# RTS5918 register map
Vendor: Realtek Semiconductor Corp.; Series: RTS5918 Series; File version: 1.00
CPU: ARMV8MML r0p0, little endian, MPU, FPU, VTOR, 3 interrupt priority bits, 8 SAU regions
Registers are 32-bit, read-write, reset 0x0 unless marked. A register's access mark holds for its fields unless they carry their own. Offsets are from the block's base; [hi:lo] are bit positions; {n}, {i} and the like mark numbered series; 'fields as' and 'values as' point back to an identical list.

## DMA — DMA Controller
Base 0x40002000
{0x0+0x58*i} SAR{i} (i=0..7) — SOURCE ADDRESS REGISTER
{0x8+0x58*i} DAR{i} (i=0..7) — DESTINATION ADDRESS REGISTER
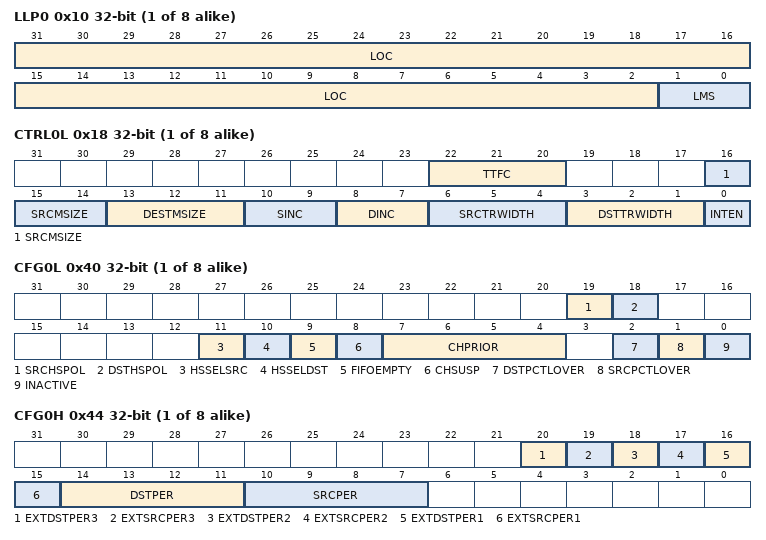
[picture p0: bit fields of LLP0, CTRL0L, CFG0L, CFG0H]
{0x10+0x58*i} LLP{i} (i=0..7) — LINKED LIST POINTER REGISTER
  [31:2] LOC — Starting Address In Memory
  [1:0] LMS — List Master Select
{0x18+0x58*i} CTRL{i}L (i=0..7) — CONTROL REGISTER LOW
  [22:20] TTFC — Transfer Type and Flow Control
    0=M2M (Memory to Memory); 1=M2P (Memory to Peripheral); 2=P2M (Peripheral to Memory); 3=P2P (Peripheral to Peripheral)
  [16:14] SRCMSIZE — Source Burst Transaction Length
    0=Transfer data item x1; 1=x4 (Transfer data item x4); 2=x8 (Transfer data item x8); 3=x16 (Transfer data item x16); 4=x32 (Transfer data item x32); 5=x64 (Transfer data item x64); 6=x128 (Transfer data item x128); 7=x256 (Transfer data item x256)
  [13:11] DESTMSIZE — Destination Burst Transaction Length
    values as SRCMSIZE
  [10:9] SINC — Source Address Increment
    0=INC (Increment); 2=FIXED (Fixed (No change)); other=NOT_USED (Do not use.)
  [8:7] DINC — Destination Address Increment
    values as SINC
  [6:4] SRCTRWIDTH — Source Transfer Width
    0=8_BIT; 1=16_BIT; 2=32_BIT; 3=64_BIT; 4=128_BIT; 5=256_BIT; other=NOT_USED (Do not use.)
  [3:1] DSTTRWIDTH — Destination Transfer Width
    values as SRCTRWIDTH
  [0] INTEN — Interrupt Enable Bit
    0=DISABLE (Disable interrup); 1=ENABLE (Enable interrup)
{0x1C+0x58*i} CTRL{i}H (i=0..7) — CONTROL REGISTER HIGH
  [31:0] BLOCKTS — Block Transfer Size
{0x40+0x58*i} CFG{i}L (i=0..7) — CONFIGURATION REGISTER LOW
  [19] SRCHSPOL — Source Handshaking Interface Polarity
  [18] DSTHSPOL — Destination Handshaking Interface Polarity
  [11] HSSELSRC — Source Software or Hardware Handshaking Select
  [10] HSSELDST — Destination Software or Hardware Handshaking Select
  [9] FIFOEMPTY ro — Indicates if there is data left in the channel FIFO
  [8] CHSUSP — Channel Suspend
  [7:4] CHPRIOR — Channel Priority
  [2] DSTPCTLOVER ro — DMA destination bus protocol finish, indicating the current read command has finished
  [1] SRCPCTLOVER ro — DMA Source bus protocol finish, indicating the current read command has finished
  [0] INACTIVE ro — Indicates if the channel is inactive
{0x44+0x58*i} CFG{i}H (i=0..7) — CONFIGURATION REGISTER HIGH
  [20] EXTDSTPER3 — The extened 6th bit of DSTPER
  [19] EXTSRCPER3 — The extened 6th bit of SRCPER
  [18] EXTDSTPER2 — The extened 5th bit of DSTPER
  [17] EXTSRCPER2 — The extened 5th bit of SRCPER
  [16] EXTDSTPER1 — The extened 4th bit of DSTPER
  [15] EXTSRCPER1 — The extened 4th bit of SRCPER
  [14:11] DSTPER — Assigns a Hardware Handshaking Interface to The Destination of Channel
  [10:7] SRCPER — Assigns a Hardware Handshaking Interface to The Source of Channel
0x2C0 RAWTFR — RAW STATUS FOR INTTFR INTERRUPT REGISTER
0x2C8 RAWBLOCK — RAW STATUS FOR INTBLOCK REGISTER
0x2D0 RAWSRCTRAN — RAW STATUS FOR INTSRCTRAN INTERRUPT REGISTER
0x2D8 RAWDSTTRAN — RAW STATUS FOR INTDSTTRAN INTERRUPT REGISTER
0x2E0 RAWERR — RAW STATUS FOR INTERR INTERRUPT REGISTER
0x2E8 STSTFR — INTERRUPT STATUS FOR INTTFR INTERRUPT REGISTER
0x2F0 STSBLOCK — INTERRUPT STATUS FOR INTBLOCK REGISTER
0x2F8 STSSRCTRAN — INTERRUPT STATUS FOR INTSRCTRAN INTERRUPT REGISTER
0x300 STSDSTTRAN — INTERRUPT STATUS FOR INTDSTTRAN INTERRUPT REGISTER
0x308 STSERR — INTERRUPT STATUS FOR INTERR INTERRUPT REGISTER
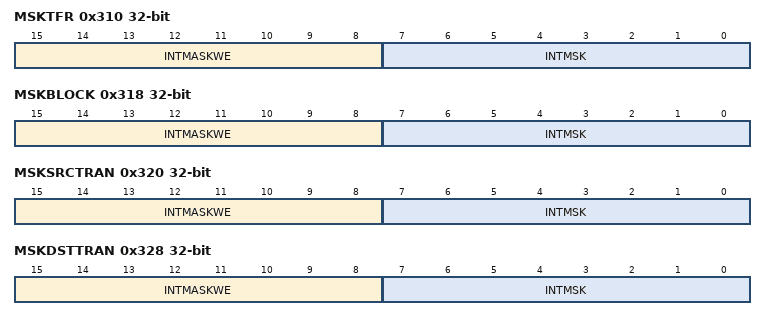
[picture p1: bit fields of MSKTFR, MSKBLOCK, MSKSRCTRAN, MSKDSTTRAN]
0x310 MSKTFR — MASK FOR INTTFR INTERRUPT REGISTER
  [15:8] INTMASKWE — Interrup Mask Write Enable
  [7:0] INTMSK — Interrupt Mask
0x318 MSKBLOCK — MASK FOR INTBLOCK REGISTER
  fields as MSKTFR
0x320 MSKSRCTRAN — MASK FOR INTSRCTRAN INTERRUPT REGISTER
  fields as MSKTFR
0x328 MSKDSTTRAN — MASK FOR INTDSTTRAN INTERRUPT REGISTER
  fields as MSKTFR
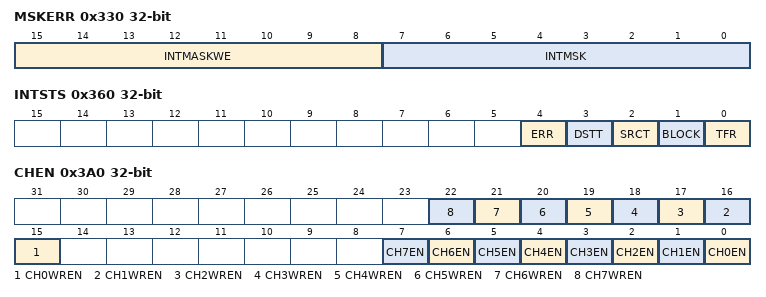
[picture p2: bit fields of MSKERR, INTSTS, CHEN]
0x330 MSKERR — MASK FOR INTERR INTERRUPT REGISTER
  fields as MSKTFR
0x338 CLRTFR — CLEAR INTERRUPT STATUS FOR INTTFR INTERRUPT REGISTER
0x340 CLRBLOCK — CLEAR INTERRUPT STATUS FOR INTBLOCK REGISTER
0x348 CLRSRCTRAN — CLEAR INTERRUPT STATUS FOR INTSRCTRAN INTERRUPT REGISTER
0x350 CLRDSTTRAN — CLEAR INTERRUPT STATUS FOR INTDSTTRAN INTERRUPT REGISTER
0x358 CLRERR — CLEAR INTERRUPT STATUS FOR INTERR INTERRUPT REGISTER
0x360 INTSTS ro — COMBINED INTERRUPT SATAUS REGISTER
  [4] ERR — OR of The Contents of StatusErr Register
  [3] DSTT — OR of The Contents of StatusDst Register
  [2] SRCT — OR of The Contents of StatusSrcTran Register
  [1] BLOCK — OR of The Contents of StatusBlock Register
  [0] TFR — OR of The Contents of StatusTfr Register
0x398 CONF — CONFIGURATION REGISTER
  [0] EN — Enable DMA Controller
    0=DISABLE (Disable DMA Controller); 1=ENABLE (Enable DMA Controller)
0x3A0 CHEN — CHANNEL ENABLE REGISTER
  [n+15] CH{n}WREN (n=0..7) — Enables DMA Channel Write Enable
    0=DISABLE (Dsiable DMA channel enable write-enable); 1=ENABLE (Enables DMA channel enable write-enable)
  [n] CH{n}EN (n=0..7) — Enables DMA Channel
    0=DISABLE (Dsiable DMA Channel); 1=ENABLE (Enables DMA Channel)
